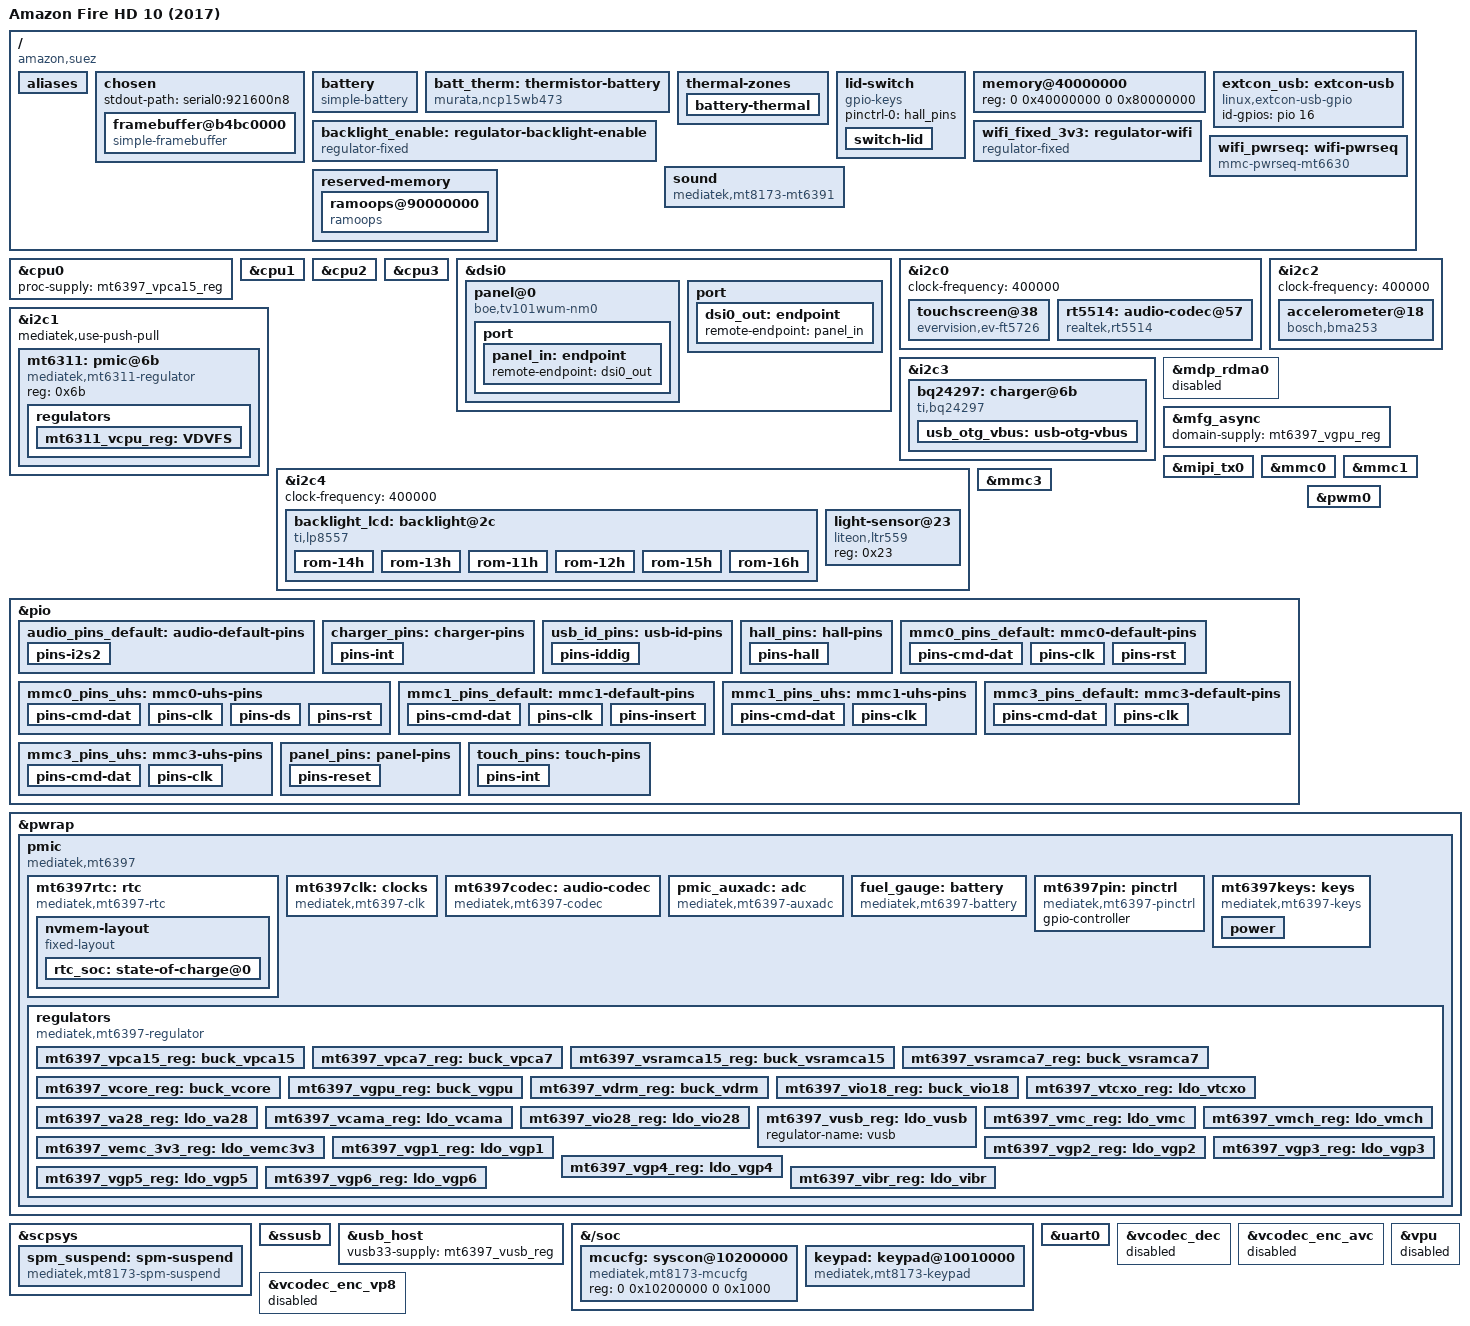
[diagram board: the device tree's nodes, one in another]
// SPDX-License-Identifier: (GPL-2.0 OR MIT)
/*
 * Copyright (c) 2026 Ryan Brue <ryanbrue.dev@gmail.com>
 *
 * Amazon Fire HD 10 (2017), codename "suez".
 */

/dts-v1/;
#include <dt-bindings/gpio/gpio.h>
#include <dt-bindings/iio/adc/mediatek,mt6397-auxadc.h>
#include <dt-bindings/input/input.h>
#include "mt8173.dtsi"

/ {
	model = "Amazon Fire HD 10 (2017)";
	compatible = "amazon,suez", "mediatek,mt8173";

	/*
	 * The vendor bootloader (LK) chooses which appended DTB to hand to the
	 * kernel by board revision: shipping only the vendor "hvt" DTB does not
	 * boot, shipping only the vendor "dvt" one does, and this unit reports
	 * version = "dvt". A DTB LK does not select is silently ignored and the
	 * kernel is never entered at all - which is why a mainline DTB carrying
	 * neither property never got control.
	 *
	 * Nothing in mainline binds to this property; it exists only so LK
	 * selects the DTB. It is kept here because the DTB is appended to the
	 * kernel image as-is; a packaging step that patched it in would be the
	 * alternative.
	 */
	version = "dvt";

	aliases {
		/* Pin the MMC indices; the SD slot otherwise renames the eMMC. */
		mmc0 = &mmc0;
		mmc1 = &mmc1;
		mmc2 = &mmc3;

		serial0 = &uart0;
	};

	chosen {
		#address-cells = <2>;
		#size-cells = <2>;
		ranges;

		stdout-path = "serial0:921600n8";

		/*
		 * LK lights the panel to draw its logo and leaves it running,
		 * which is the only console this device has until the display
		 * driver binds: the UART is not brought out on a retail unit.
		 *
		 * This window is not reserved here on purpose. LK rewrites
		 * /memory and injects its own no-map carve-outs for the
		 * framebuffer, the secure OS and the VPU pool before entering
		 * the kernel, so a second reservation for the same range only
		 * earns an "OVERLAP DETECTED" from of_reserved_mem.
		 */
		framebuffer@b4bc0000 {
			compatible = "simple-framebuffer";
			reg = <0 0xb4bc0000 0 (1216 * 1920 * 4)>;
			width = <1200>;
			height = <1920>;
			/* Scanlines are padded to 1216 px; a wrong stride shears the image. */
			stride = <(1216 * 4)>;
			format = "a8r8g8b8";
		};
	};

	/*
	 * The pack. Everything the gauge needs is on the fuel-gauge node below;
	 * this node carries only what the power-supply core reads for the
	 * generic properties. The figures are the vendor's for the Desay cell
	 * this unit is fitted with (IDME productid2 0831 = BATTERY_ID_DSY;
	 * ATL units read 0841), from suez_bat_setting.dtsi battery_dsy_setting:
	 * q_max_pos_25 and the 25 C profile's end points. Nothing here is
	 * measured on this board.
	 */
	battery: battery {
		compatible = "simple-battery";
		device-chemistry = "lithium-ion";
		voltage-min-design-microvolt = <3352000>;
		voltage-max-design-microvolt = <4321000>;
		charge-full-design-microamp-hours = <6348000>;
		constant-charge-voltage-max-microvolt = <4352000>;

		/*
		 * The vendor's characterisation of the Desay cell, from
		 * suez_bat_setting.dtsi battery_dsy_setting, taken at -10, 0,
		 * 10, 25 and 50 C (its t0, t1, t1_5, t2 and t3).
		 *
		 * The vendor spells its curves as depth of discharge against
		 * millivolts, and indexes them by charge rather than by
		 * percentage: a row is a fixed 54 mAh step, so the percentage it
		 * carries is round(row * 54 * 100 / Qmax) and about one row in
		 * six repeats the percentage before it. Resampled here onto the
		 * percentage itself, averaging the rows that share one, at 1 %
		 * below 15 % and 3 % above it - finer where the curve is steep.
		 * Against the vendor's own 120 rows that is worth at most one
		 * point of reported capacity, which is less than those rows
		 * disagree among themselves between two characterisation
		 * temperatures.
		 */
		ocv-capacity-celsius = <(-10) 0 10 25 50>;
		ocv-capacity-table-0 =
				<4275000 100>, <4252000 99>, <4215000 96>,
				<4177000 93>, <4149000 90>, <4121000 87>,
				<4092000 84>, <4076000 81>, <4030000 78>,
				<3982000 75>, <3959000 72>, <3945000 69>,
				<3929000 66>, <3901000 63>, <3879000 60>,
				<3860000 57>, <3843000 54>, <3833000 51>,
				<3823000 48>, <3811000 45>, <3803000 42>,
				<3796000 39>, <3789000 36>, <3782000 33>,
				<3776000 30>, <3769000 27>, <3756000 24>,
				<3746000 21>, <3736000 18>, <3716000 15>,
				<3711000 14>, <3704000 13>, <3697000 12>,
				<3694000 11>, <3693000 10>, <3692000 9>,
				<3691000 8>, <3689000 7>, <3686000 6>,
				<3676000 5>, <3651000 4>, <3613000 3>,
				<3565000 2>, <3504000 1>, <3419000 0>;
		ocv-capacity-table-1 =
				<4287000 100>, <4267000 99>, <4225000 96>,
				<4192000 93>, <4166000 90>, <4130000 87>,
				<4105000 84>, <4084000 81>, <4055000 78>,
				<4003000 75>, <3969000 72>, <3956000 69>,
				<3940000 66>, <3923000 63>, <3894000 60>,
				<3867000 57>, <3850000 54>, <3832000 51>,
				<3822000 48>, <3812000 45>, <3802000 42>,
				<3796000 39>, <3789000 36>, <3786000 33>,
				<3783000 30>, <3779000 27>, <3773000 24>,
				<3761000 21>, <3750000 18>, <3730000 15>,
				<3725000 14>, <3719000 13>, <3712000 12>,
				<3706000 11>, <3704000 10>, <3701000 9>,
				<3698000 8>, <3695000 7>, <3692000 6>,
				<3685000 5>, <3670000 4>, <3639000 3>,
				<3565000 2>, <3457000 1>, <3335000 0>;
		ocv-capacity-table-2 =
				<4309000 100>, <4292000 99>, <4248000 96>,
				<4219000 93>, <4188000 90>, <4156000 87>,
				<4129000 84>, <4095000 81>, <4080000 78>,
				<4037000 75>, <3994000 72>, <3967000 69>,
				<3958000 66>, <3942000 63>, <3917000 60>,
				<3884000 57>, <3860000 54>, <3846000 51>,
				<3830000 48>, <3820000 45>, <3808000 42>,
				<3801000 39>, <3791000 36>, <3786000 33>,
				<3780000 30>, <3776000 27>, <3770000 24>,
				<3758000 21>, <3749000 18>, <3729000 15>,
				<3725000 14>, <3719000 13>, <3711000 12>,
				<3705000 11>, <3702000 10>, <3699000 9>,
				<3698000 8>, <3697000 7>, <3694000 6>,
				<3686000 5>, <3681000 4>, <3632000 3>,
				<3561000 2>, <3495000 1>, <3400000 0>;
		ocv-capacity-table-3 =
				<4321000 100>, <4304000 99>, <4260000 96>,
				<4231000 93>, <4194000 90>, <4167000 87>,
				<4131000 84>, <4104000 81>, <4073000 78>,
				<4058000 75>, <4002000 72>, <3976000 69>,
				<3966000 66>, <3946000 63>, <3924000 60>,
				<3895000 57>, <3863000 54>, <3843000 51>,
				<3831000 48>, <3817000 45>, <3808000 42>,
				<3798000 39>, <3791000 36>, <3783000 33>,
				<3777000 30>, <3767000 27>, <3759000 24>,
				<3747000 21>, <3739000 18>, <3721000 15>,
				<3716000 14>, <3712000 13>, <3702000 12>,
				<3693000 11>, <3691000 10>, <3691000 9>,
				<3690000 8>, <3688000 7>, <3685000 6>,
				<3678000 5>, <3662000 4>, <3628000 3>,
				<3586000 2>, <3531000 1>, <3460000 0>;
		ocv-capacity-table-4 =
				<4337000 100>, <4321000 99>, <4270000 96>,
				<4238000 93>, <4199000 90>, <4171000 87>,
				<4135000 84>, <4109000 81>, <4075000 78>,
				<4051000 75>, <4020000 72>, <3996000 69>,
				<3972000 66>, <3950000 63>, <3927000 60>,
				<3902000 57>, <3870000 54>, <3850000 51>,
				<3834000 48>, <3820000 45>, <3810000 42>,
				<3799000 39>, <3792000 36>, <3783000 33>,
				<3777000 30>, <3758000 27>, <3746000 24>,
				<3733000 21>, <3724000 18>, <3707000 15>,
				<3702000 14>, <3698000 13>, <3692000 12>,
				<3682000 11>, <3679000 10>, <3678000 9>,
				<3678000 8>, <3676000 7>, <3674000 6>,
				<3666000 5>, <3647000 4>, <3614000 3>,
				<3572000 2>, <3519000 1>, <3450000 0>;
	};

	/*
	 * The pack thermistor, on the PMIC's AUXADC rather than the SoC's,
	 * under the pull-up the vendor calls rbat_pull_up_r and
	 * rbat_pull_up_volt. Its 19-point table in suez_bat_setting.dtsi is a
	 * 47 kOhm-at-25C NTC and agrees with mainline's ncp15wb473 curve to
	 * within 0.5 C over the -20 to 70 C it covers.
	 */
	batt_therm: thermistor-battery {
		compatible = "murata,ncp15wb473";
		io-channels = <&pmic_auxadc MT6397_AUXADC_BAT_TEMP>;
		pullup-uv = <1200000>;
		pullup-ohm = <24000>;
		pulldown-ohm = <0>;
		#thermal-sensor-cells = <0>;
	};

	thermal-zones {
		/* Read on demand by the fuel gauge, which does its own polling. */
		battery-thermal {
			polling-delay = <0>;
			polling-delay-passive = <0>;
			thermal-sensors = <&batt_therm>;
		};
	};

	lid-switch {
		compatible = "gpio-keys";
		pinctrl-names = "default";
		pinctrl-0 = <&hall_pins>;

		switch-lid {
			label = "hall-effect-sensor";
			/*
			 * Open-drain hall output: the magnet in the cover pulls
			 * it down, so asserted (lid closed) is low. The vendor
			 * board file spells the same thing as an active-low
			 * level interrupt with an unused GPIO flag.
			 */
			gpios = <&pio 124 GPIO_ACTIVE_LOW>;
			linux,input-type = <EV_SW>;
			linux,code = <SW_LID>;
			debounce-interval = <20>;
		};
	};

	memory@40000000 {
		device_type = "memory";
		reg = <0 0x40000000 0 0x80000000>;
	};

	/* USB ID pin on GPIO16 (IDDIG): low means an OTG adapter is attached. */
	extcon_usb: extcon-usb {
		compatible = "linux,extcon-usb-gpio";
		id-gpios = <&pio 16 GPIO_ACTIVE_HIGH>;
	};

	backlight_enable: regulator-backlight-enable {
		compatible = "regulator-fixed";
		regulator-name = "backlight_enable";
		gpio = <&mt6397pin 14 GPIO_ACTIVE_HIGH>;
		enable-active-high;
	};

	/*
	 * The always-on rail feeding the MT6630's SDIO interface. Not a real
	 * switchable supply -- the chip's power control is its PMU_EN GPIO
	 * (pio 8), not a regulator -- but the MMC core refuses to initialise
	 * a card on a host whose ocr_avail is empty ("no support for card's
	 * volts", seen on hardware), and ocr_avail comes from vmmc. A fixed
	 * always-on 3.3 V regulator is the honest description of the rail and
	 * gives the core a voltage window to accept the chip's OCR with.
	 * mt8173-elm models its SDIO WiFi power the same way (sdio_fixed_3v3).
	 */
	wifi_fixed_3v3: regulator-wifi {
		compatible = "regulator-fixed";
		regulator-name = "wifi_fixed_3v3";
		regulator-min-microvolt = <3300000>;
		regulator-max-microvolt = <3300000>;
		regulator-always-on;
	};

	/*
	 * MT6630 power-up, in-kernel (vendor mtk_wcn_cmb_hw_pwr_on): PMU_EN
	 * (pio 8) and RST (pio 38) low 20 ms, PMU_EN high 50 ms, RST high
	 * 50 ms. Same proven timing as the userspace bring-up ritual. With
	 * this the chip answers the boot-time SDIO scan and BT exists from
	 * boot; the powerdown/reset naming is the pwrseq-sd8787 binding's.
	 */
	wifi_pwrseq: wifi-pwrseq {
		compatible = "mmc-pwrseq-mt6630";
		powerdown-gpios = <&pio 8 GPIO_ACTIVE_HIGH>;
		reset-gpios = <&pio 38 GPIO_ACTIVE_HIGH>;
	};

	sound {
		compatible = "mediatek,mt8173-mt6391";
		mediatek,audio-codec = <&mt6397codec>;
		/*
		 * Capture comes from the RT5514 over I2S2, not from the MT6397.
		 * The AFE carries that stream to I17/I18 -> O09/O10 -> VUL;
		 * this adds the back end that lets that leg power up.
		 */
		mediatek,capture-codec = <&rt5514>;
		mediatek,platform = <&afe>;
		pinctrl-names = "default";
		pinctrl-0 = <&audio_pins_default>;
	};

	reserved-memory {
		#address-cells = <2>;
		#size-cells = <2>;
		ranges;

		/* Not the vendor ram_console at 0x44400000; recovery clears that. */
		ramoops@90000000 {
			compatible = "ramoops";
			reg = <0 0x90000000 0 0x80000>;
			console-size = <0x40000>;
			record-size = <0x8000>;
			ftrace-size = <0x20000>;
		};
	};
};

&cpu0 {
	proc-supply = <&mt6397_vpca15_reg>;
};

&cpu1 {
	proc-supply = <&mt6397_vpca15_reg>;
	enable-method = "mediatek,mt8173-smp";
};

&cpu2 {
	proc-supply = <&mt6311_vcpu_reg>;
	sram-supply = <&mt6397_vsramca7_reg>;
	enable-method = "mediatek,mt8173-smp";
};

&cpu3 {
	proc-supply = <&mt6311_vcpu_reg>;
	sram-supply = <&mt6397_vsramca7_reg>;
	enable-method = "mediatek,mt8173-smp";
};

&dsi0 {
	status = "okay";
	#address-cells = <1>;
	#size-cells = <0>;

	panel@0 {
		compatible = "boe,tv101wum-nm0", "novatek,nt51021";
		reg = <0>;

		vdd-supply = <&mt6397_vgp6_reg>;
		avdd-supply = <&mt6397_vgp6_reg>;
		havdd-supply = <&mt6397_vgp6_reg>;

		reset-gpios = <&pio 105 GPIO_ACTIVE_LOW>;
		pinctrl-names = "default";
		pinctrl-0 = <&panel_pins>;

		backlight = <&backlight_lcd>;

		port {
			panel_in: endpoint {
				remote-endpoint = <&dsi0_out>;
			};
		};
	};

	port {
		dsi0_out: endpoint {
			remote-endpoint = <&panel_in>;
		};
	};
};

&i2c0 {
	status = "okay";
	clock-frequency = <400000>;

	touchscreen@38 {
		compatible = "evervision,ev-ft5726";
		reg = <0x38>;
		interrupts-extended = <&pio 14 IRQ_TYPE_EDGE_FALLING>;
		reset-gpios = <&mt6397pin 12 GPIO_ACTIVE_LOW>;
		pinctrl-names = "default";
		pinctrl-0 = <&touch_pins>;
		vcc-supply = <&mt6397_vgp3_reg>;
		iovcc-supply = <&mt6397_vgp4_reg>;

		/* Required: edt-ft5x06 cannot read the sensor counts on an EV_FT part. */
		touchscreen-size-x = <1200>;
		touchscreen-size-y = <1920>;
	};

	rt5514: audio-codec@57 {
		compatible = "realtek,rt5514";
		reg = <0x57>;
		interrupts-extended = <&pio 0 IRQ_TYPE_LEVEL_HIGH>;
		#sound-dai-cells = <0>;
	};
};

&i2c1 {
	status = "okay";
	mediatek,use-push-pull;

	mt6311: pmic@6b {
		compatible = "mediatek,mt6311-regulator";
		reg = <0x6b>;

		regulators {
			/* Pinning Vproc to one voltage hangs the machine under sustained load. */
			mt6311_vcpu_reg: VDVFS {
				regulator-name = "VDVFS";
				regulator-min-microvolt = <600000>;
				regulator-max-microvolt = <1393750>;
				regulator-ramp-delay = <10000>;
				regulator-always-on;
			};

			/* No VBIASN: it is enable-only, and constraints fail registration. */
		};
	};
};

&i2c2 {
	status = "okay";
	clock-frequency = <400000>;

	accelerometer@18 {
		compatible = "bosch,bma253";
		reg = <0x18>;
		mount-matrix = "0", "-1", "0",
			       "-1", "0", "0",
			       "0", "0", "-1";
	};
};

&i2c3 {
	status = "okay";

	bq24297: charger@6b {
		compatible = "ti,bq24297";
		reg = <0x6b>;
		interrupts-extended = <&pio 9 IRQ_TYPE_EDGE_FALLING>;
		pinctrl-names = "default";
		pinctrl-0 = <&charger_pins>;

		/* No fuel gauge on this part, so the battery class would read 0/0. */
		omit-battery-class;

		/*
		 * The charger's boost converter is the only 5 V source for the
		 * micro-B port, so this is what powers a USB OTG peripheral.
		 * The vendor's p0-vbus-mode = <1> ("by charger ic") is the same
		 * arrangement.
		 */
		usb_otg_vbus: usb-otg-vbus { };
	};
};

&i2c4 {
	status = "okay";
	clock-frequency = <400000>;

	backlight_lcd: backlight@2c {
		compatible = "ti,lp8557";
		reg = <0x2c>;
		enable-supply = <&backlight_enable>;

		dev-ctrl = /bits/ 8 <0x47>;
		init-brt = /bits/ 8 <0x64>;

		/*
		 * Written in the order the vendor driver writes its
		 * "eeprom_data" table, which is not register order.
		 */

		/* 4 V OV, 4 output LED strings enabled */
		rom-14h {
			rom-addr = /bits/ 8 <0x14>;
			rom-val = /bits/ 8 <0x0f>;
		};
		/* boost frequency 1 MHz */
		rom-13h {
			rom-addr = /bits/ 8 <0x13>;
			rom-val = /bits/ 8 <0x01>;
		};
		/* full-scale LED current 23 mA */
		rom-11h {
			rom-addr = /bits/ 8 <0x11>;
			rom-val = /bits/ 8 <0x06>;
		};
		/* 19.5 kHz */
		rom-12h {
			rom-addr = /bits/ 8 <0x12>;
			rom-val = /bits/ 8 <0x2b>;
		};
		/* light smoothing, 100 ms */
		rom-15h {
			rom-addr = /bits/ 8 <0x15>;
			rom-val = /bits/ 8 <0x42>;
		};
		/* max boost voltage 28 V, adaptive */
		rom-16h {
			rom-addr = /bits/ 8 <0x16>;
			rom-val = /bits/ 8 <0xe0>;
		};
	};

	light-sensor@23 {
		compatible = "liteon,ltr559";
		reg = <0x23>;
	};
};

/* Consumes the VPU, which does not run here. See &vpu below. */
&mdp_rdma0 {
	status = "disabled";
};

&mfg_async {
	domain-supply = <&mt6397_vgpu_reg>;
};

/* Also the "hs" clock provider for dsi0, so mtk-dsi needs it. */
&mipi_tx0 {
	status = "okay";
};

&mmc0 {
	status = "okay";
	pinctrl-names = "default", "state_uhs";
	pinctrl-0 = <&mmc0_pins_default>;
	pinctrl-1 = <&mmc0_pins_uhs>;
	bus-width = <8>;
	max-frequency = <200000000>;
	cap-mmc-highspeed;
	mmc-hs200-1_8v;
	mmc-hs400-1_8v;
	hs400-ds-delay = <0x14015>;
	cap-mmc-hw-reset;
	non-removable;
	mediatek,hs200-cmd-int-delay = <30>;
	mediatek,hs400-cmd-int-delay = <14>;
	mediatek,hs400-cmd-resp-sel-rising;
	vmmc-supply = <&mt6397_vemc_3v3_reg>;
	vqmmc-supply = <&mt6397_vio18_reg>;
	/* Reparent MSDC50_0 to MSDCPLL_D2, or HS200 tuning fails -EILSEQ. */
	assigned-clocks = <&topckgen CLK_TOP_MSDC50_0_SEL>;
	assigned-clock-parents = <&topckgen CLK_TOP_MSDCPLL_D2>;
};

&mmc1 {
	status = "okay";
	pinctrl-names = "default", "state_uhs";
	pinctrl-0 = <&mmc1_pins_default>;
	pinctrl-1 = <&mmc1_pins_uhs>;
	bus-width = <4>;
	max-frequency = <200000000>;
	cap-sd-highspeed;
	sd-uhs-sdr50;
	sd-uhs-sdr104;
	/*
	 * The socket shorts this line to ground while the slot is empty and
	 * opens it once a card is seated, so the pull-up in mmc1_pins_default
	 * is what produces the "present" level: active HIGH, where
	 * mt8173-elm's socket is wired the other way up and declares
	 * active low.
	 */
	cd-gpios = <&pio 1 GPIO_ACTIVE_HIGH>;
	vmmc-supply = <&mt6397_vmch_reg>;
	vqmmc-supply = <&mt6397_vmc_reg>;
	mediatek,hs200-cmd-int-delay = <4>;
};

/*
 * The MT6630 WiFi/BT/GPS/FM combo chip, on SDIO. The chip enumerates once
 * its PMU_EN (pio 8) and RST (pio 38) lines are driven high, which the
 * mmc-pwrseq-mt6630 sequence above does.
 *
 * Properties follow the vendor &mmc3 node (suez_dvt.dts): 4-bit,
 * non-removable, no card detect. The vendor names no regulators at all,
 * because there is nothing to name: the pads sit on an always-on rail and the
 * chip's power is the PMU_EN GPIO, not a slot regulator. mtk-sd.yaml requires
 * both vmmc-supply and vqmmc-supply, so that rail is described as a fixed
 * regulator and both properties point at it -- see the comment on them below.
 *
 * The vendor also claims SDR50/SDR104. UHS is left off here: switching to
 * 1.8 V signalling needs a vqmmc regulator that can actually deliver 1.8 V,
 * and this one is fixed at 3.3 V, so the switch would fail. The slot runs at
 * high-speed (50 MHz), which is what the vendor's own stack settles on too.
 *
 * Pin lists are the vendor's (22-25 data, 27 cmd, 26 clk), structured like
 * mt8173-elm's mmc3 groups.
 */
&mmc3 {
	status = "okay";
	pinctrl-names = "default", "state_uhs";
	pinctrl-0 = <&mmc3_pins_default>;
	pinctrl-1 = <&mmc3_pins_uhs>;
	bus-width = <4>;
	max-frequency = <200000000>;
	cap-sd-highspeed;
	/* the MT6630 signals RX via the SDIO in-band interrupt (the vendor
	 * stack registers no EINT for MT6630-on-SDIO); without this cap the
	 * mmc core's CCCR-INTx poll fallback never fired the handler */
	cap-sdio-irq;
	non-removable;

	/*
	 * Do not power the chip down for system suspend. mmc_sdio_suspend()
	 * calls mmc_power_off() unless MMC_PM_KEEP_POWER is set, and here that
	 * runs the pwrseq below and drops PMU_EN and RST -- a full power cycle
	 * of a chip whose ROM patches and WLAN firmware are downloaded to its
	 * RAM at probe. Both function drivers request the flag in their
	 * .suspend, and sdio_set_host_pm_flags() rejects it unless
	 * host->pm_caps allows it, which is what this property sets.
	 *
	 * It is not a fiction on this board: nothing can switch the MT6630's
	 * supply. The vendor's &mmc3 has no vmmc-supply at all, and its
	 * connectivity-combo node leaves gpio_combo_ldo_en_pin and
	 * gpio_combo_pmuv28_en_pin commented out, so PMU_EN and RST are the
	 * only power control that exists.
	 */
	keep-power-in-suspend;

	/*
	 * A fixed always-on regulator, because the core needs an ocr mask to
	 * initialise the card and there is no switchable supply to name.
	 *
	 * vqmmc names the same rail. The bus signals at 3.3 V -- measured, as
	 * /sys/kernel/debug/mmc2/ios reporting "signal voltage: 0 (3.30 V)"
	 * while the link runs SD high-speed at 50 MHz -- and it never switches,
	 * because no sd-uhs-* property asks it to. So one 3.3 V rail describes
	 * both the card supply and the I/O supply, which is the situation
	 * mtk-sd.yaml's required vqmmc-supply is asking about. The physical net
	 * was not traced; what is known is the level the bus is observed to
	 * signal at and that nothing here can change it.
	 */
	vmmc-supply = <&wifi_fixed_3v3>;
	vqmmc-supply = <&wifi_fixed_3v3>;
	mmc-pwrseq = <&wifi_pwrseq>;
};

&pio {
	/*
	 * I2S2, which is how the RT5514 delivers the internal microphones.
	 * The pins are the I2S0 group muxed to their I2S2 functions, exactly
	 * as suez_dvt.dts's audio_pins_default does. MCK is included because
	 * the RT5514 takes its 12.288 MHz master clock from the SoC.
	 */
	audio_pins_default: audio-default-pins {
		pins-i2s2 {
			pinmux = <MT8173_PIN_128_I2S0_LRCK__FUNC_I2S2_WS>,
				 <MT8173_PIN_129_I2S0_BCK__FUNC_I2S2_BCK>,
				 <MT8173_PIN_130_I2S0_MCK__FUNC_I2S2_MCK>,
				 <MT8173_PIN_132_I2S0_DATA1__FUNC_I2S2_DI_2>;
			bias-pull-down;
		};
	};

	charger_pins: charger-pins {
		pins-int {
			pinmux = <MT8173_PIN_9_EINT9__FUNC_GPIO9>;
			input-enable;
			bias-pull-up;
		};
	};

	/*
	 * The port's ID pin. Pulled up so it floats high (peripheral) with
	 * nothing or a plain cable attached, and reads low only when an OTG
	 * adapter grounds it, as on mt8173-evb.
	 */
	usb_id_pins: usb-id-pins {
		pins-iddig {
			pinmux = <MT8173_PIN_16_IDDIG__FUNC_IDDIG>;
			bias-pull-up;
		};
	};

	hall_pins: hall-pins {
		pins-hall {
			pinmux = <MT8173_PIN_124_KPCOL2__FUNC_GPIO124>;
			input-enable;
			bias-pull-up;
		};
	};

	mmc0_pins_default: mmc0-default-pins {
		pins-cmd-dat {
			pinmux = <MT8173_PIN_57_MSDC0_DAT0__FUNC_MSDC0_DAT0>,
				 <MT8173_PIN_58_MSDC0_DAT1__FUNC_MSDC0_DAT1>,
				 <MT8173_PIN_59_MSDC0_DAT2__FUNC_MSDC0_DAT2>,
				 <MT8173_PIN_60_MSDC0_DAT3__FUNC_MSDC0_DAT3>,
				 <MT8173_PIN_61_MSDC0_DAT4__FUNC_MSDC0_DAT4>,
				 <MT8173_PIN_62_MSDC0_DAT5__FUNC_MSDC0_DAT5>,
				 <MT8173_PIN_63_MSDC0_DAT6__FUNC_MSDC0_DAT6>,
				 <MT8173_PIN_64_MSDC0_DAT7__FUNC_MSDC0_DAT7>,
				 <MT8173_PIN_66_MSDC0_CMD__FUNC_MSDC0_CMD>;
			input-enable;
			bias-pull-up;
		};

		pins-clk {
			pinmux = <MT8173_PIN_65_MSDC0_CLK__FUNC_MSDC0_CLK>;
			bias-pull-down;
		};

		pins-rst {
			pinmux = <MT8173_PIN_68_MSDC0_RST___FUNC_MSDC0_RSTB>;
			bias-pull-up;
		};
	};

	mmc0_pins_uhs: mmc0-uhs-pins {
		pins-cmd-dat {
			pinmux = <MT8173_PIN_57_MSDC0_DAT0__FUNC_MSDC0_DAT0>,
				 <MT8173_PIN_58_MSDC0_DAT1__FUNC_MSDC0_DAT1>,
				 <MT8173_PIN_59_MSDC0_DAT2__FUNC_MSDC0_DAT2>,
				 <MT8173_PIN_60_MSDC0_DAT3__FUNC_MSDC0_DAT3>,
				 <MT8173_PIN_61_MSDC0_DAT4__FUNC_MSDC0_DAT4>,
				 <MT8173_PIN_62_MSDC0_DAT5__FUNC_MSDC0_DAT5>,
				 <MT8173_PIN_63_MSDC0_DAT6__FUNC_MSDC0_DAT6>,
				 <MT8173_PIN_64_MSDC0_DAT7__FUNC_MSDC0_DAT7>,
				 <MT8173_PIN_66_MSDC0_CMD__FUNC_MSDC0_CMD>;
			input-enable;
			drive-strength = <6>;
			bias-pull-up = <MTK_PUPD_SET_R1R0_01>;
		};

		pins-clk {
			pinmux = <MT8173_PIN_65_MSDC0_CLK__FUNC_MSDC0_CLK>;
			drive-strength = <6>;
			bias-pull-down = <MTK_PUPD_SET_R1R0_10>;
		};

		pins-ds {
			pinmux = <MT8173_PIN_67_MSDC0_DSL__FUNC_MSDC0_DSL>;
			drive-strength = <8>;
			bias-pull-down = <MTK_PUPD_SET_R1R0_10>;
		};

		pins-rst {
			pinmux = <MT8173_PIN_68_MSDC0_RST___FUNC_MSDC0_RSTB>;
			bias-pull-up;
		};
	};

	mmc1_pins_default: mmc1-default-pins {
		pins-cmd-dat {
			pinmux = <MT8173_PIN_73_MSDC1_DAT0__FUNC_MSDC1_DAT0>,
				 <MT8173_PIN_74_MSDC1_DAT1__FUNC_MSDC1_DAT1>,
				 <MT8173_PIN_75_MSDC1_DAT2__FUNC_MSDC1_DAT2>,
				 <MT8173_PIN_76_MSDC1_DAT3__FUNC_MSDC1_DAT3>,
				 <MT8173_PIN_78_MSDC1_CMD__FUNC_MSDC1_CMD>;
			input-enable;
			drive-strength = <4>;
			bias-pull-up = <MTK_PUPD_SET_R1R0_01>;
		};

		pins-clk {
			pinmux = <MT8173_PIN_77_MSDC1_CLK__FUNC_MSDC1_CLK>;
			bias-pull-down = <MTK_PUPD_SET_R1R0_10>;
			drive-strength = <4>;
		};

		/* Pulled up so that an empty slot, which grounds it, reads low. */
		pins-insert {
			pinmux = <MT8173_PIN_1_EINT1__FUNC_GPIO1>;
			bias-pull-up;
		};
	};

	mmc1_pins_uhs: mmc1-uhs-pins {
		pins-cmd-dat {
			pinmux = <MT8173_PIN_73_MSDC1_DAT0__FUNC_MSDC1_DAT0>,
				 <MT8173_PIN_74_MSDC1_DAT1__FUNC_MSDC1_DAT1>,
				 <MT8173_PIN_75_MSDC1_DAT2__FUNC_MSDC1_DAT2>,
				 <MT8173_PIN_76_MSDC1_DAT3__FUNC_MSDC1_DAT3>,
				 <MT8173_PIN_78_MSDC1_CMD__FUNC_MSDC1_CMD>;
			input-enable;
			drive-strength = <10>;
			bias-pull-up = <MTK_PUPD_SET_R1R0_01>;
		};

		pins-clk {
			pinmux = <MT8173_PIN_77_MSDC1_CLK__FUNC_MSDC1_CLK>;
			drive-strength = <10>;
			bias-pull-down = <MTK_PUPD_SET_R1R0_10>;
		};
	};

	mmc3_pins_default: mmc3-default-pins {
		pins-cmd-dat {
			pinmux = <MT8173_PIN_22_MSDC3_DAT0__FUNC_MSDC3_DAT0>,
				 <MT8173_PIN_23_MSDC3_DAT1__FUNC_MSDC3_DAT1>,
				 <MT8173_PIN_24_MSDC3_DAT2__FUNC_MSDC3_DAT2>,
				 <MT8173_PIN_25_MSDC3_DAT3__FUNC_MSDC3_DAT3>,
				 <MT8173_PIN_27_MSDC3_CMD__FUNC_MSDC3_CMD>;
			input-enable;
			drive-strength = <4>;
			bias-pull-up = <MTK_PUPD_SET_R1R0_10>;
		};

		pins-clk {
			pinmux = <MT8173_PIN_26_MSDC3_CLK__FUNC_MSDC3_CLK>;
			drive-strength = <4>;
			bias-pull-down = <MTK_PUPD_SET_R1R0_10>;
		};
	};

	mmc3_pins_uhs: mmc3-uhs-pins {
		pins-cmd-dat {
			pinmux = <MT8173_PIN_22_MSDC3_DAT0__FUNC_MSDC3_DAT0>,
				 <MT8173_PIN_23_MSDC3_DAT1__FUNC_MSDC3_DAT1>,
				 <MT8173_PIN_24_MSDC3_DAT2__FUNC_MSDC3_DAT2>,
				 <MT8173_PIN_25_MSDC3_DAT3__FUNC_MSDC3_DAT3>,
				 <MT8173_PIN_27_MSDC3_CMD__FUNC_MSDC3_CMD>;
			input-enable;
			drive-strength = <4>;
			bias-pull-up = <MTK_PUPD_SET_R1R0_10>;
		};

		pins-clk {
			pinmux = <MT8173_PIN_26_MSDC3_CLK__FUNC_MSDC3_CLK>;
			drive-strength = <4>;
			bias-pull-down = <MTK_PUPD_SET_R1R0_10>;
		};
	};

	panel_pins: panel-pins {
		pins-reset {
			pinmux = <MT8173_PIN_105_MSDC2_CMD__FUNC_GPIO105>;
			bias-disable;
		};
	};

	touch_pins: touch-pins {
		pins-int {
			pinmux = <MT8173_PIN_14_EINT14__FUNC_GPIO14>;
			input-enable;
			bias-disable;
		};
	};
};

/* Unused as a backlight, but DISP_PWM is on the MT8173 main display path. */
&pwm0 {
	status = "okay";
};

&pwrap {
	pmic: pmic {
		compatible = "mediatek,mt6397";
		/* EINT 5, not the 11 of mt8173-elm and evb, or the line never fires. */
		interrupts-extended = <&pio 5 IRQ_TYPE_LEVEL_HIGH>;
		interrupt-controller;
		#interrupt-cells = <2>;

		mt6397rtc: rtc {
			compatible = "mediatek,mt6397-rtc";

			/*
			 * The first of the RTC's spare bytes, which MediaTek
			 * documents as the fuel gauge's and the vendor kernel
			 * uses for exactly that. Seven bits, because the
			 * eighth is reserved.
			 */
			nvmem-layout {
				compatible = "fixed-layout";
				#address-cells = <1>;
				#size-cells = <1>;

				rtc_soc: state-of-charge@0 {
					reg = <0x0 0x1>;
					bits = <0 7>;
				};
			};
		};

		mt6397clk: clocks {
			compatible = "mediatek,mt6397-clk";
			#clock-cells = <1>;
		};

		mt6397codec: audio-codec {
			compatible = "mediatek,mt6397-codec";
			mediatek,speaker-mode = <0>;
			mediatek,adc-warmup-time-us = <10000>;
			mediatek,dmic-warmup-time-us = <45000>;
		};

		/*
		 * The PMIC's auxiliary ADC. It is the only way to read the
		 * battery voltage on this board: the SoC AUXADC channels are
		 * board thermistors (the vendor's cust_adc.dtsi describes only
		 * temperature0/1 plus an RF channel), and the BQ24297 is a
		 * charger with no ADC, which is why bq24190-battery reports
		 * neither voltage_now nor capacity. Its ISENSE channel is the pack
		 * voltage, which is where the vendor measures it on a board with a
		 * power-path charger, and BAT_TEMP the pack thermistor.
		 */
		pmic_auxadc: adc {
			compatible = "mediatek,mt6397-auxadc";
			#io-channel-cells = <1>;
		};

		/*
		 * The PMIC's fuel gauge, running MediaTek's battery-meter
		 * algorithm on the hardware coulomb counter, exactly as Fire OS
		 * did (CONFIG_SOC_BY_HW_FG). Every number below is the vendor's
		 * own tuning for the Desay pack in this unit, copied from
		 * suez_bat_setting.dtsi battery_dsy_setting and the suez_1v0
		 * defaults in mt_bm_data.c; none is measured here. The tables
		 * are indexed by the battery's ocv-capacity-celsius, so all of
		 * them are at -10, 0, 10, 25 and 50 C (the vendor's t0, t1,
		 * t1_5, t2 and t3), and they are resampled onto the same
		 * percentages as ocv-capacity-table-N, 45 points each.
		 */
		fuel_gauge: battery {
			compatible = "mediatek,mt6397-battery";
			io-channels = <&pmic_auxadc MT6397_AUXADC_ISENSE>;
			io-channel-names = "voltage";
			monitored-battery = <&battery>;
			nvmem-cells = <&rtc_soc>;
			nvmem-cell-names = "state-of-charge";
			power-supplies = <&bq24297>;
			shunt-resistor-micro-ohms = <10000>;	/* r_fg_value */
			mediatek,car-tune-value = <101>;
			mediatek,ocv2cv-transform;
			/* vendor cv_current 6000, in units of 0.1 mA */
			mediatek,cv-current-microamp = <600000>;
			mediatek,poweron-low-capacity-tolerance = <0>;
			/* q_max_pos_* and q_max_pos_*_h_current */
			mediatek,qmax-microamp-hours =
				<5947000 6141000 6210000 6348000 6345000>;
			mediatek,qmax-high-current-microamp-hours =
				<5739000 5568000 5936000 6130000 6133000>;

			/*
			 * The internal resistance the pack has at each point of the
			 * matching ocv-capacity-table, from the same
			 * characterisation. battery.yaml has no property for this:
			 * resistance-temp-table only scales one resistance with
			 * temperature, and this one varies along the discharge curve
			 * as well, by more than a factor of two at -10 C. The
			 * resistance is in microohms, like the voltage beside it and
			 * like factory-internal-resistance-micro-ohms.
			 */
			mediatek,ocv-resistance-table-0 =
				<4275000 254000>, <4252000 254000>, <4215000 269000>,
				<4177000 276000>, <4149000 320000>, <4121000 368000>,
				<4092000 396000>, <4076000 404000>, <4030000 381000>,
				<3982000 396000>, <3959000 405000>, <3945000 414000>,
				<3929000 421000>, <3901000 411000>, <3879000 401000>,
				<3860000 385000>, <3843000 175000>, <3833000 123000>,
				<3823000 106000>, <3811000 96000>, <3803000 93000>,
				<3796000 93000>, <3789000 92000>, <3782000 92000>,
				<3776000 88000>, <3769000 83000>, <3756000 77000>,
				<3746000 76000>, <3736000 75000>, <3716000 74000>,
				<3711000 74000>, <3704000 74000>, <3697000 73000>,
				<3694000 73000>, <3693000 73000>, <3692000 74000>,
				<3691000 75000>, <3689000 76000>, <3686000 78000>,
				<3676000 80000>, <3651000 78000>, <3613000 81000>,
				<3565000 84000>, <3504000 90000>, <3419000 98000>;
			mediatek,ocv-resistance-table-1 =
				<4287000 230000>, <4267000 230000>, <4225000 252000>,
				<4192000 256000>, <4166000 262000>, <4130000 269000>,
				<4105000 269000>, <4084000 239000>, <4055000 245000>,
				<4003000 211000>, <3969000 268000>, <3956000 274000>,
				<3940000 280000>, <3923000 277000>, <3894000 267000>,
				<3867000 258000>, <3850000 253000>, <3832000 255000>,
				<3822000 257000>, <3812000 261000>, <3802000 266000>,
				<3796000 269000>, <3789000 274000>, <3786000 277000>,
				<3783000 285000>, <3779000 295000>, <3773000 304000>,
				<3761000 317000>, <3750000 334000>, <3730000 368000>,
				<3725000 373000>, <3719000 385000>, <3712000 393000>,
				<3706000 402000>, <3704000 417000>, <3701000 438000>,
				<3698000 463000>, <3695000 484000>, <3692000 507000>,
				<3685000 533000>, <3670000 559000>, <3639000 575000>,
				<3565000 636000>, <3457000 729000>, <3335000 822000>;
			mediatek,ocv-resistance-table-2 =
				<4309000 123000>, <4292000 123000>, <4248000 132000>,
				<4219000 133000>, <4188000 136000>, <4156000 141000>,
				<4129000 140000>, <4095000 147000>, <4080000 153000>,
				<4037000 148000>, <3994000 147000>, <3967000 146000>,
				<3958000 154000>, <3942000 154000>, <3917000 149000>,
				<3884000 136000>, <3860000 129000>, <3846000 130000>,
				<3830000 129000>, <3820000 130000>, <3808000 134000>,
				<3801000 133000>, <3791000 136000>, <3786000 136000>,
				<3780000 138000>, <3776000 141000>, <3770000 139000>,
				<3758000 143000>, <3749000 143000>, <3729000 144000>,
				<3725000 148000>, <3719000 151000>, <3711000 152000>,
				<3705000 151000>, <3702000 155000>, <3699000 160000>,
				<3698000 164000>, <3697000 168000>, <3694000 179000>,
				<3686000 182000>, <3681000 134000>, <3632000 196000>,
				<3561000 223000>, <3495000 250000>, <3400000 285000>;
			mediatek,ocv-resistance-table-3 =
				<4321000 74000>, <4304000 74000>, <4260000 73000>,
				<4231000 73000>, <4194000 74000>, <4167000 75000>,
				<4131000 77000>, <4104000 78000>, <4073000 83000>,
				<4058000 84000>, <4002000 79000>, <3976000 83000>,
				<3966000 86000>, <3946000 86000>, <3924000 89000>,
				<3895000 84000>, <3863000 70000>, <3843000 68000>,
				<3831000 68000>, <3817000 69000>, <3808000 70000>,
				<3798000 72000>, <3791000 74000>, <3783000 73000>,
				<3777000 74000>, <3767000 72000>, <3759000 71000>,
				<3747000 71000>, <3739000 73000>, <3721000 74000>,
				<3716000 75000>, <3712000 76000>, <3702000 74000>,
				<3693000 74000>, <3691000 74000>, <3691000 75000>,
				<3690000 76000>, <3688000 76000>, <3685000 78000>,
				<3678000 80000>, <3662000 78000>, <3628000 79000>,
				<3586000 83000>, <3531000 86000>, <3460000 93000>;
			mediatek,ocv-resistance-table-4 =
				<4337000 50000>, <4321000 50000>, <4270000 51000>,
				<4238000 52000>, <4199000 53000>, <4171000 53000>,
				<4135000 54000>, <4109000 54000>, <4075000 55000>,
				<4051000 56000>, <4020000 57000>, <3996000 58000>,
				<3972000 60000>, <3950000 62000>, <3927000 65000>,
				<3902000 65000>, <3870000 56000>, <3850000 55000>,
				<3834000 55000>, <3820000 55000>, <3810000 55000>,
				<3799000 57000>, <3792000 57000>, <3783000 59000>,
				<3777000 60000>, <3758000 54000>, <3746000 55000>,
				<3733000 55000>, <3724000 56000>, <3707000 55000>,
				<3702000 55000>, <3698000 56000>, <3692000 56000>,
				<3682000 54000>, <3679000 55000>, <3678000 56000>,
				<3678000 57000>, <3676000 57000>, <3674000 58000>,
				<3666000 59000>, <3647000 58000>, <3614000 59000>,
				<3572000 61000>, <3519000 63000>, <3450000 68000>;
		};

		mt6397pin: pinctrl {
			compatible = "mediatek,mt6397-pinctrl";
			gpio-controller;
			#gpio-cells = <2>;
		};

		mt6397keys: keys {
			compatible = "mediatek,mt6397-keys";
			mediatek,long-press-mode = <1>;
			power-off-time-sec = <0>;

			power {
				linux,keycodes = <KEY_POWER>;
				wakeup-source;
			};
		};

		regulators {
			compatible = "mediatek,mt6397-regulator";

			mt6397_vpca15_reg: buck_vpca15 {
				regulator-name = "vpca15";
				regulator-min-microvolt = < 700000>;
				regulator-max-microvolt = <1350000>;
				regulator-ramp-delay = <12500>;
				regulator-always-on;
			};

			mt6397_vpca7_reg: buck_vpca7 {
				regulator-name = "vpca7";
				regulator-min-microvolt = < 700000>;
				regulator-max-microvolt = <1350000>;
				regulator-ramp-delay = <12500>;
				regulator-enable-ramp-delay = <115>;
			};

			mt6397_vsramca15_reg: buck_vsramca15 {
				regulator-name = "vsramca15";
				regulator-min-microvolt = < 700000>;
				regulator-max-microvolt = <1350000>;
				regulator-ramp-delay = <12500>;
				regulator-always-on;
			};

			/* The A72 cluster's Vsram despite the name; cpufreq couples the pair. */
			mt6397_vsramca7_reg: buck_vsramca7 {
				regulator-name = "vsramca7";
				regulator-min-microvolt = < 700000>;
				regulator-max-microvolt = <1350000>;
				regulator-ramp-delay = <12500>;
				regulator-always-on;
			};

			mt6397_vcore_reg: buck_vcore {
				regulator-name = "vcore";
				regulator-min-microvolt = < 700000>;
				regulator-max-microvolt = <1350000>;
				regulator-ramp-delay = <12500>;
				regulator-always-on;
			};

			/* 150 us per suez_evt/dvt, not the 115 us of evb and elm. */
			mt6397_vgpu_reg: buck_vgpu {
				regulator-name = "vgpu";
				regulator-min-microvolt = < 700000>;
				regulator-max-microvolt = <1350000>;
				regulator-ramp-delay = <12500>;
				regulator-enable-ramp-delay = <150>;
			};

			mt6397_vdrm_reg: buck_vdrm {
				regulator-name = "vdrm";
				regulator-min-microvolt = <1200000>;
				regulator-max-microvolt = <1400000>;
				regulator-ramp-delay = <12500>;
				regulator-always-on;
			};

			mt6397_vio18_reg: buck_vio18 {
				regulator-name = "vio18";
				regulator-min-microvolt = <1620000>;
				regulator-max-microvolt = <1980000>;
				regulator-ramp-delay = <12500>;
				regulator-always-on;
			};

			mt6397_vtcxo_reg: ldo_vtcxo {
				regulator-name = "vtcxo";
				regulator-always-on;
			};

			mt6397_va28_reg: ldo_va28 {
				regulator-name = "va28";
				regulator-always-on;
			};

			mt6397_vcama_reg: ldo_vcama {
				regulator-name = "vcama";
				regulator-min-microvolt = <1500000>;
				regulator-max-microvolt = <2800000>;
				regulator-enable-ramp-delay = <218>;
			};

			mt6397_vio28_reg: ldo_vio28 {
				regulator-name = "vio28";
				regulator-always-on;
			};

			mt6397_vusb_reg: ldo_vusb {
				regulator-name = "vusb";
			};

			mt6397_vmc_reg: ldo_vmc {
				regulator-name = "vmc";
				regulator-min-microvolt = <1800000>;
				regulator-max-microvolt = <3300000>;
				regulator-enable-ramp-delay = <218>;
			};

			mt6397_vmch_reg: ldo_vmch {
				regulator-name = "vmch";
				regulator-min-microvolt = <3000000>;
				regulator-max-microvolt = <3300000>;
				regulator-enable-ramp-delay = <218>;
			};

			mt6397_vemc_3v3_reg: ldo_vemc3v3 {
				regulator-name = "vemc_3v3";
				regulator-min-microvolt = <3000000>;
				regulator-max-microvolt = <3300000>;
				regulator-enable-ramp-delay = <218>;
			};

			mt6397_vgp1_reg: ldo_vgp1 {
				regulator-name = "vcamd";
				regulator-min-microvolt = <1220000>;
				regulator-max-microvolt = <3300000>;
				regulator-enable-ramp-delay = <240>;
			};

			mt6397_vgp2_reg: ldo_vgp2 {
				regulator-name = "vcamio";
				regulator-min-microvolt = <1000000>;
				regulator-max-microvolt = <3300000>;
				regulator-enable-ramp-delay = <218>;
			};

			mt6397_vgp3_reg: ldo_vgp3 {
				regulator-name = "vcamaf";
				regulator-min-microvolt = <1200000>;
				regulator-max-microvolt = <3300000>;
				regulator-enable-ramp-delay = <218>;
			};

			mt6397_vgp4_reg: ldo_vgp4 {
				regulator-name = "vgp4";
				regulator-min-microvolt = <1200000>;
				regulator-max-microvolt = <3300000>;
				regulator-enable-ramp-delay = <218>;
			};

			mt6397_vgp5_reg: ldo_vgp5 {
				regulator-name = "vgp5";
				regulator-min-microvolt = <1200000>;
				regulator-max-microvolt = <3000000>;
				regulator-enable-ramp-delay = <218>;
			};

			mt6397_vgp6_reg: ldo_vgp6 {
				regulator-name = "vgp6";
				regulator-min-microvolt = <1200000>;
				regulator-max-microvolt = <3300000>;
				regulator-enable-ramp-delay = <218>;
			};

			mt6397_vibr_reg: ldo_vibr {
				regulator-name = "vibr";
				regulator-min-microvolt = <1300000>;
				regulator-max-microvolt = <3300000>;
				regulator-enable-ramp-delay = <218>;
			};
		};
	};
};

&scpsys {
	/*
	 * Suspend-to-RAM. This board's firmware is PSCI 0.2, which predates
	 * SYSTEM_SUSPEND, so the kernel is never given platform_suspend_ops
	 * and /sys/power/mem_sleep offers only s2idle. mtk-spm-suspend drives
	 * the SPM from the kernel instead, the way the vendor kernel does.
	 *
	 * This is deliberately a board property rather than something in
	 * mt8173.dtsi: mt8173-elm and mt8173-oak ship ARM Trusted Firmware,
	 * where BL31 does this same work at EL3, and adding the node there
	 * would put two suspend implementations on the same hardware.
	 */
	spm_suspend: spm-suspend {
		compatible = "mediatek,mt8173-spm-suspend";

		/* SPM IRQ0, as the vendor's scpsys node has it (155..160). */
		interrupts = <GIC_SPI 155 IRQ_TYPE_LEVEL_LOW>;

		/* MP0_AXI_CONFIG, for ACINACTM around the WFI */
		mediatek,mcucfg = <&mcucfg>;

		/*
		 * The rails feeding the still-powered CPU must not follow
		 * SRCLKEN down while the SoC is asleep.
		 */
		mediatek,pmic = <&pmic>;

		/*
		 * fscp_ck is parked on the crystal for the duration, because
		 * the SPM stops the PLL it normally runs from.
		 */
		clocks = <&topckgen CLK_TOP_SCP_SEL>,
			 <&topckgen CLK_TOP_SYSPLL1_D2>,
			 <&clk26m>;
		clock-names = "scp_sel", "syspll1_d2", "clk26m";
	};
};

/*
 * The single micro-B port is the charger input and the only USB port. It is
 * dual-role: peripheral by default, and host when an OTG adapter grounds the
 * ID pin, with the charger's boost converter sourcing VBUS. The vendor kernel
 * detected the role the same way (otg-mode = <1>, "iddig-eint").
 */
&ssusb {
	vusb33-supply = <&mt6397_vusb_reg>;
	vbus-supply = <&usb_otg_vbus>;
	extcon = <&extcon_usb>;
	dr_mode = "otg";
	maximum-speed = "high-speed";
	pinctrl-names = "default";
	pinctrl-0 = <&usb_id_pins>;
	status = "okay";
};

&usb_host {
	vusb33-supply = <&mt6397_vusb_reg>;
	status = "okay";
};

&{/soc} {
	/*
	 * mt8173.dtsi has no MCUCFG node, but powering the A72 cluster needs
	 * CA15L_MISCDBG to deassert ACINACTM. Naming follows mt2712e.dtsi's
	 * "mediatek,mt2712-mcucfg", "syscon".
	 */
	mcucfg: syscon@10200000 {
		compatible = "mediatek,mt8173-mcucfg", "syscon";
		reg = <0 0x10200000 0 0x1000>;
	};

	/*
	 * The keypad controller, which carries the volume rocker. mt8173.dtsi
	 * does not describe it at all, and mainline has no mt8173 keypad
	 * driver -- but mt6779-keypad drives this block unmodified, so the
	 * node only needs the fallback compatible. Everything below was
	 * measured on this unit rather than assumed:
	 *
	 *   - The block is register-compatible. LK leaves it enabled and the
	 *     vendor's hal_kpd.h agrees offset for offset (STA 0x00,
	 *     MEM1..5 0x04..0x14, DEBOUNCE 0x18, SEL 0x20, EN 0x24), and
	 *     KP_MEM1..4 read 0x0000ffff / KP_MEM5 0x000000ff -- i.e. 16
	 *     valid bits per register, 72 keys, exactly what mt6779-keypad
	 *     already assumes and what the vendor spells KPD_NUM_KEYS.
	 *
	 *   - Pressing a key clears its bit in eight places at a stride of
	 *     nine (key 0,9,18..63 for one, 1,10,19..64 for the other), so
	 *     mt6779-keypad's single-group mapping -- row = key / 9,
	 *     col = key % 9 -- is right for this SoC too, and both keys sit
	 *     on row 0.
	 *
	 * num-rows/num-columns describe the *bit layout*, not the two keys
	 * actually fitted. A press asserts all eight row slots of its column
	 * even when KP_SEL enables a single row (verified by reprogramming
	 * KP_SEL and re-measuring), and the interrupt handler maps every
	 * changed bit through MATRIX_SCAN_CODE before looking it up. Declaring
	 * one row would therefore index past the end of the keymap; 8x9 keeps
	 * every possible (row, col) inside it, and the unfitted positions stay
	 * KEY_RESERVED and are dropped by the input core. Enabling the full
	 * geometry costs nothing: with KP_SEL at 0xfff0 the idle state is
	 * still all ones, so no unconnected line reads as pressed.
	 *
	 * The keymap follows the vendor's mediatek,kpd-hw-init-map in
	 * cust_kpd_8173.dtsi, <115 114 ...>: hardware key 0 is KEY_VOLUMEUP
	 * and key 1 is KEY_VOLUMEDOWN. Both kernels index that map by the
	 * hardware key number with a stride of nine, so key 0 is (row 0,
	 * column 0) either way.
	 *
	 * That map describes the unswapped orientation. Fire OS turns the
	 * volume keys around at runtime through an ALSA control (VOLKEY_NORMAL
	 * / VOLKEY_SWAP in mt_afe_pcm_dl1.c, next to the audio LR_NORMAL /
	 * LR_SWAP control, enabled by CONFIG_KPD_VOLUME_KEY_SWAP=y in
	 * suez_defconfig), so the keys flip together with the speaker channels
	 * when the tablet is turned over. A static keymap can only describe
	 * one orientation, and the vendor's baseline is the one to describe.
	 *
	 * debounce-delay-ms is LK's KP_DEBOUNCE of 0x400 expressed in the
	 * driver's units: it writes debounce * 32, and 32 * 32 = 1024, which
	 * is also the vendor's mediatek,kpd-key-debounce.
	 */
	keypad: keypad@10010000 {
		compatible = "mediatek,mt8173-keypad",
			     "mediatek,mt6779-keypad";
		reg = <0 0x10010000 0 0x1000>;
		interrupts = <GIC_SPI 154 IRQ_TYPE_EDGE_FALLING>;
		clocks = <&infracfg CLK_INFRA_KP>;
		clock-names = "kpd";
		wakeup-source;
		debounce-delay-ms = <32>;
		keypad,num-rows = <8>;
		keypad,num-columns = <9>;
		linux,keymap = <MATRIX_KEY(0, 0, KEY_VOLUMEUP)
				MATRIX_KEY(0, 1, KEY_VOLUMEDOWN)>;
	};
};

&uart0 {
	status = "okay";
};

/* Consumes the VPU, which does not run here. See &vpu below. */
&vcodec_dec {
	status = "disabled";
};

&vcodec_enc_avc {
	status = "disabled";
};

&vcodec_enc_vp8 {
	status = "disabled";
};

/*
 * Disabled: the firmware never starts here and mtk_vpu_suspend() then
 * returns -EIO, aborting every suspend. Its four consumers resolve the
 * mediatek,vpu phandle through vpu_get_plat_device() and WARN_ON() a
 * disabled node, so they are disabled too rather than left to backtrace.
 */
&vpu {
	status = "disabled";
};
